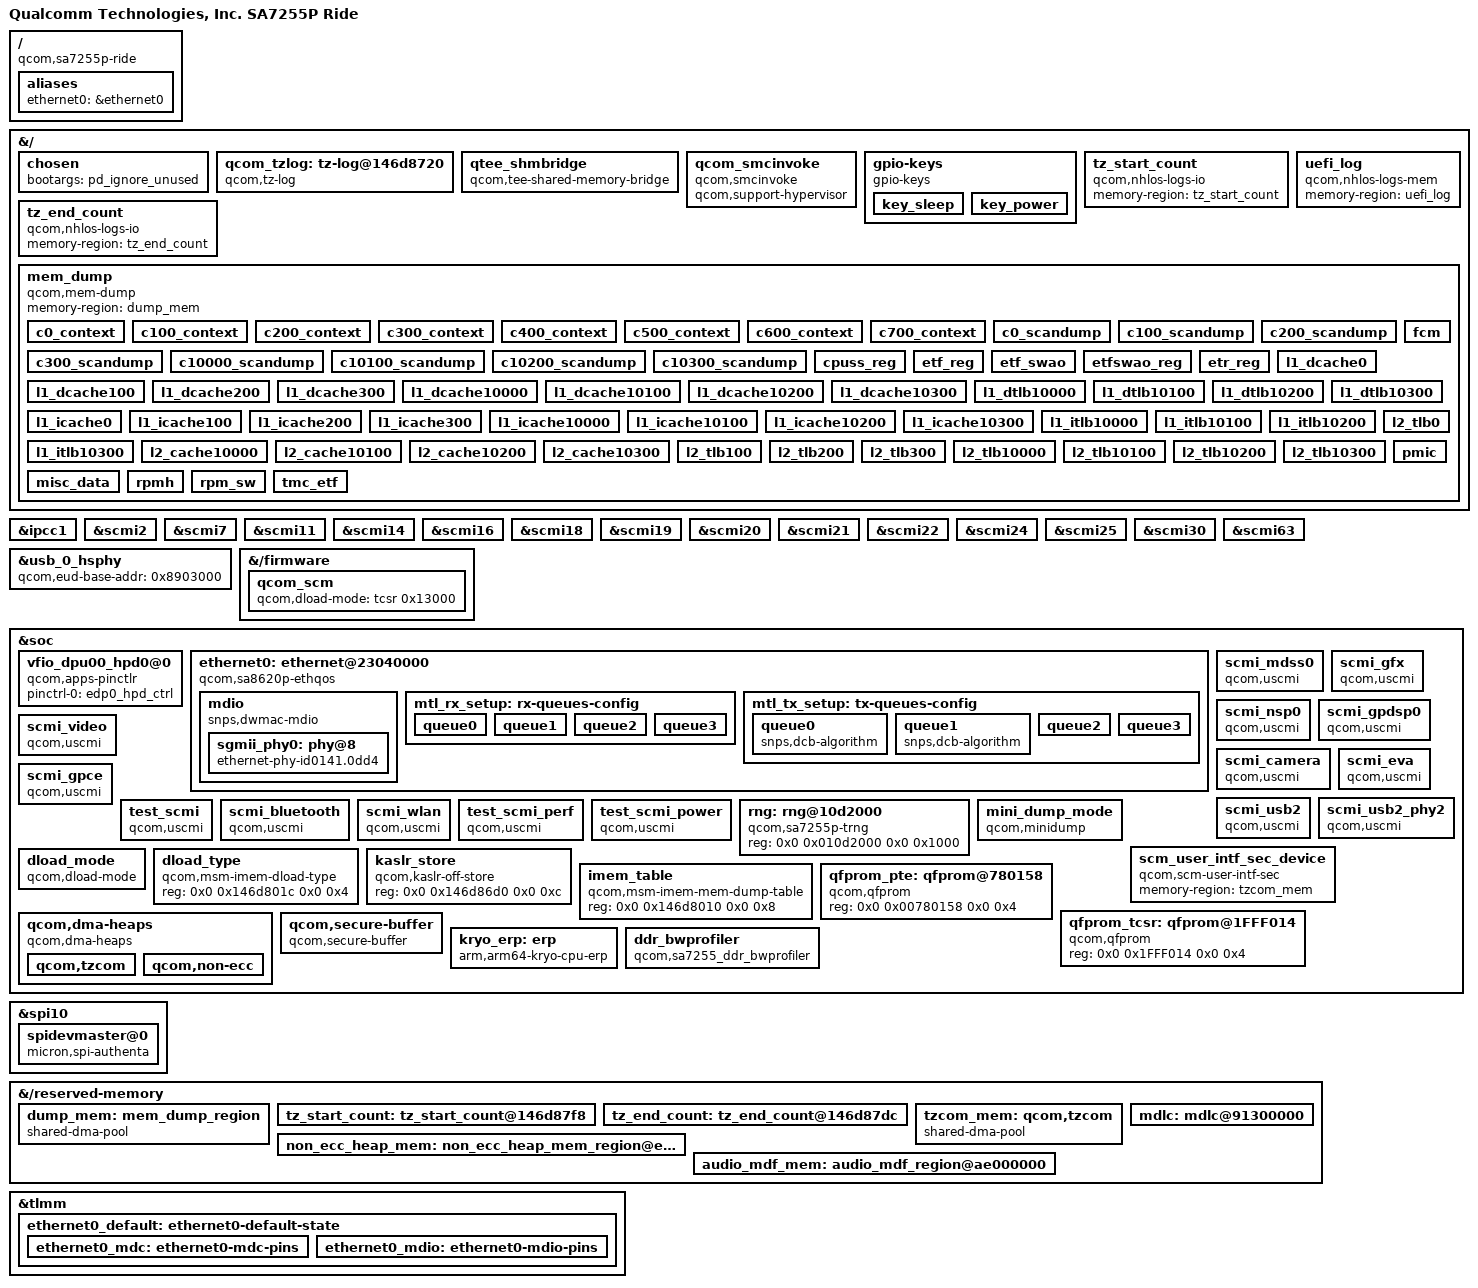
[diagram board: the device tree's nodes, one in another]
// SPDX-License-Identifier: BSD-3-Clause
/*
 * Copyright (c) Qualcomm Technologies, Inc. and/or its subsidiaries.
 */

/dts-v1/;
/plugin/;

#include <dt-bindings/interrupt-controller/irq.h>
#include <dt-bindings/interrupt-controller/arm-gic.h>
#include <dt-bindings/arm/qcom_dma_heap_dt_constants.h>
#include <dt-bindings/input/input.h>
#include <dt-bindings/gpio/gpio.h>
#include <oot-dt-bindings/qcom-ipcc.h>
#include "sa7255p-pinctrl.dtsi"
#include "sa7255p-vfio.dtsi"
#include "sa7255p-cnss.dtsi"

/ {
	model = "Qualcomm Technologies, Inc. SA7255P Ride";
	compatible = "qcom,sa7255p-ride","qcom,sa7255p";

	aliases {
		ethernet0 = &ethernet0;
	};
};

&{/} {

	chosen {
		bootargs = "pd_ignore_unused";
	};

	qcom_tzlog: tz-log@146d8720 {
		compatible = "qcom,tz-log";
		reg = <0 0x146d8720 0 0x3000>;
		qcom,hyplog-enabled;
		qcom,support-hypervisor;
		hyplog-address-offset = <0x410>;
		hyplog-size-offset = <0x414>;
	};

	qtee_shmbridge {
		compatible = "qcom,tee-shared-memory-bridge";
		qcom,support-hypervisor;
		memory-region = <&cma>;
	};

	qcom_smcinvoke {
		compatible = "qcom,smcinvoke";
		qcom,support-hypervisor;
	};

	gpio-keys {
		compatible = "gpio-keys";

		key_sleep {
			label = "sleep";
			linux,code = <KEY_SLEEP>;
			gpios = <&tlmm 3 GPIO_ACTIVE_HIGH>;
			linux,input-type = <1>;
			debounce-interval = <0>;
			wakeup-source;
			wakeup-event-action = <1>;
		};

		key_power {
			label = "power";
			linux,code = <KEY_POWER>;
			gpios = <&tlmm 56 GPIO_ACTIVE_HIGH>;
			linux,input-type = <1>;
			debounce-interval = <0>;
			wakeup-source;
			wakeup-event-action = <1>;
		};
	};

	tz_start_count {
		compatible = "qcom,nhlos-logs-io", "qcom,nhlos-logs";
		memory-region = <&tz_start_count>;
	};

	tz_end_count {
		compatible = "qcom,nhlos-logs-io", "qcom,nhlos-logs";
		memory-region = <&tz_end_count>;
	};

	uefi_log {
		compatible = "qcom,nhlos-logs-mem", "qcom,nhlos-logs";
		memory-region = <&uefi_log>;
	};

	mem_dump {
		compatible = "qcom,mem-dump";
		memory-region = <&dump_mem>;

		c0_context {
			qcom,dump-size = <0x800>;
			qcom,dump-id = <0x0>;
		};

		c100_context {
			qcom,dump-size = <0x800>;
			qcom,dump-id = <0x1>;
		};

		c200_context {
			qcom,dump-size = <0x800>;
			qcom,dump-id = <0x2>;
		};

		c300_context {
			qcom,dump-size = <0x800>;
			qcom,dump-id = <0x3>;
		};

		c400_context {
			qcom,dump-size = <0x800>;
			qcom,dump-id = <0x4>;
		};

		c500_context {
			qcom,dump-size = <0x800>;
			qcom,dump-id = <0x5>;
		};

		c600_context {
			qcom,dump-size = <0x800>;
			qcom,dump-id = <0x6>;
		};

		c700_context {
			qcom,dump-size = <0x800>;
			qcom,dump-id = <0x7>;
		};

		c0_scandump: c0_scandump {
			qcom,dump-size = <0x40000>;
			qcom,dump-id = <0x130>;
		};

		c100_scandump: c100_scandump {
			qcom,dump-size = <0x40000>;
			qcom,dump-id = <0x131>;
		};

		c200_scandump: c200_scandump {
			qcom,dump-size = <0x40000>;
			qcom,dump-id = <0x132>;
		};

		c300_scandump: c300_scandump {
			qcom,dump-size = <0x40000>;
			qcom,dump-id = <0x133>;
		};

		c10000_scandump: c10000_scandump {
			qcom,dump-size = <0x40000>;
			qcom,dump-id = <0x134>;
		};

		c10100_scandump: c10100_scandump {
			qcom,dump-size = <0x40000>;
			qcom,dump-id = <0x135>;
		};

		c10200_scandump: c10200_scandump {
			qcom,dump-size = <0x40000>;
			qcom,dump-id = <0x136>;
		};

		c10300_scandump: c10300_scandump {
			qcom,dump-size = <0x40000>;
			qcom,dump-id = <0x137>;
		};

		cpuss_reg: cpuss_reg {
			qcom,dump-size = <0x20000>;
			qcom,dump-id = <0xef>;
		};

		etf_reg {
			qcom,dump-size = <0x1000>;
			qcom,dump-id = <0x101>;
		};

		etf_swao {
			qcom,dump-size = <0x8400>;
			qcom,dump-id = <0xf1>;
		};

		etfswao_reg {
			qcom,dump-size = <0x1000>;
			qcom,dump-id = <0x102>;
		};

		etr_reg {
			qcom,dump-size = <0x1000>;
			qcom,dump-id = <0x100>;
		};

		fcm {
			qcom,dump-size = <0x8400>;
			qcom,dump-id = <0xee>;
		};

		l1_dcache0 {
			qcom,dump-size = <0x12100>;
			qcom,dump-id = <0x80>;
		};

		l1_dcache100 {
			qcom,dump-size = <0x12100>;
			qcom,dump-id = <0x81>;
		};

		l1_dcache200 {
			qcom,dump-size = <0x12100>;
			qcom,dump-id = <0x82>;
		};

		l1_dcache300 {
			qcom,dump-size = <0x12100>;
			qcom,dump-id = <0x83>;
		};

		l1_dcache10000 {
			qcom,dump-size = <0x12100>;
			qcom,dump-id = <0x84>;
		};

		l1_dcache10100 {
			qcom,dump-size = <0x12100>;
			qcom,dump-id = <0x85>;
		};

		l1_dcache10200 {
			qcom,dump-size = <0x12100>;
			qcom,dump-id = <0x86>;
		};

		l1_dcache10300 {
			qcom,dump-size = <0x12100>;
			qcom,dump-id = <0x87>;
		};

		l1_dtlb10000 {
			qcom,dump-size = <0x300>;
			qcom,dump-id = <0x44>;
		};

		l1_dtlb10100 {
			qcom,dump-size = <0x300>;
			qcom,dump-id = <0x45>;
		};

		l1_dtlb10200 {
			qcom,dump-size = <0x300>;
			qcom,dump-id = <0x46>;
		};

		l1_dtlb10300 {
			qcom,dump-size = <0x300>;
			qcom,dump-id = <0x47>;
		};

		l1_icache0 {
			qcom,dump-size = <0x26100>;
			qcom,dump-id = <0x60>;
		};

		l1_icache100 {
			qcom,dump-size = <0x26100>;
			qcom,dump-id = <0x61>;
		};

		l1_icache200 {
			qcom,dump-size = <0x26100>;
			qcom,dump-id = <0x62>;
		};

		l1_icache300 {
			qcom,dump-size = <0x26100>;
			qcom,dump-id = <0x63>;
		};

		l1_icache10000 {
			qcom,dump-size = <0x26100>;
			qcom,dump-id = <0x64>;
		};

		l1_icache10100 {
			qcom,dump-size = <0x26100>;
			qcom,dump-id = <0x65>;
		};

		l1_icache10200 {
			qcom,dump-size = <0x26100>;
			qcom,dump-id = <0x66>;
		};

		l1_icache10300 {
			qcom,dump-size = <0x26100>;
			qcom,dump-id = <0x67>;
		};

		l1_itlb10000 {
			qcom,dump-size = <0x300>;
			qcom,dump-id = <0x24>;
		};

		l1_itlb10100 {
			qcom,dump-size = <0x300>;
			qcom,dump-id = <0x25>;
		};

		l1_itlb10200 {
			qcom,dump-size = <0x300>;
			qcom,dump-id = <0x26>;
		};

		l1_itlb10300 {
			qcom,dump-size = <0x300>;
			qcom,dump-id = <0x27>;
		};

		l2_cache10000 {
			qcom,dump-size = <0x90100>;
			qcom,dump-id = <0xc4>;
		};

		l2_cache10100 {
			qcom,dump-size = <0x90100>;
			qcom,dump-id = <0xc5>;
		};

		l2_cache10200 {
			qcom,dump-size = <0x90100>;
			qcom,dump-id = <0xc6>;
		};

		l2_cache10300 {
			qcom,dump-size = <0x90100>;
			qcom,dump-id = <0xc7>;
		};

		l2_tlb0 {
			qcom,dump-size = <0x6100>;
			qcom,dump-id = <0x120>;
		};

		l2_tlb100 {
			qcom,dump-size = <0x6100>;
			qcom,dump-id = <0x121>;
		};

		l2_tlb200 {
			qcom,dump-size = <0x6100>;
			qcom,dump-id = <0x122>;
		};

		l2_tlb300 {
			qcom,dump-size = <0x6100>;
			qcom,dump-id = <0x123>;
		};

		l2_tlb10000 {
			qcom,dump-size = <0x6100>;
			qcom,dump-id = <0x124>;
		};

		l2_tlb10100 {
			qcom,dump-size = <0x6100>;
			qcom,dump-id = <0x125>;
		};

		l2_tlb10200 {
			qcom,dump-size = <0x6100>;
			qcom,dump-id = <0x126>;
		};

		l2_tlb10300 {
			qcom,dump-size = <0x6100>;
			qcom,dump-id = <0x127>;
		};

		misc_data {
			qcom,dump-size = <0x1000>;
			qcom,dump-id = <0xe8>;
		};

		pmic {
			qcom,dump-size = <0x80000>;
			qcom,dump-id = <0xe4>;
		};

		rpmh {
			qcom,dump-size = <0x2000000>;
			qcom,dump-id = <0xec>;
		};

		rpm_sw {
			qcom,dump-size = <0x28000>;
			qcom,dump-id = <0xea>;
		};

		tmc_etf {
			qcom,dump-size = <0x10000>;
			qcom,dump-id = <0xf0>;
		};
	};
};

&ipcc1 {
	status = "okay";
};

&scmi2 {
	status = "okay";
};

&scmi7 {
	status = "okay";
};

&scmi11 {
	status = "okay";
};

&scmi14 {
	status = "okay";
};

&scmi16 {
	status = "okay";
};

&scmi18 {
	status = "okay";
};

&scmi19 {
	status = "okay";
};

&scmi20 {
	status = "okay";
};

&scmi21 {
	status = "okay";
};

&scmi22 {
	status = "okay";
};

&scmi24 {
	status = "okay";
};

&scmi25 {
	status = "okay";
};

&scmi30 {
	status = "okay";
};

&scmi63 {
	status = "okay";
};

&usb_0_hsphy {
	qcom,eud-base-addr = <0x8903000>;
};

&{/firmware} {
        qcom_scm {
                qcom,dload-mode = <&tcsr 0x13000>;
        };
};

&soc {
	vfio_dpu00_hpd0@0 {
		compatible = "qcom,apps-pinctlr";
		pinctrl-names = "default";
		pinctrl-0 = <&edp0_hpd_ctrl>;
	};

	ethernet0: ethernet@23040000 {
			compatible = "qcom,sa8620p-ethqos";
			reg = <0x0 0x23040000 0x0 0x10000>,
				<0x0 0x23056000 0x0 0x100>;
			reg-names = "stmmaceth", "rgmii";

			interrupts = <GIC_SPI 946 IRQ_TYPE_LEVEL_HIGH>,
				<GIC_SPI 782 IRQ_TYPE_LEVEL_HIGH>;
			interrupt-names = "macirq", "sfty";

			iommus = <&apps_smmu 0x120 0xf>;
			dma-coherent;

			snps,tso;
			snps,pbl = <32>;
			rx-fifo-depth = <16384>;
			tx-fifo-depth = <20480>;

	};
	scmi_mdss0 {
		compatible = "qcom,uscmi";
		power-domains = <&scmi16_dvfs 0>;
		power-domain-names = "perf";
		qcom,dev-name = "scmi_mdss0";
	};

	scmi_gfx {
		compatible = "qcom,uscmi";
		power-domains = <&scmi18_dvfs 0>;
		power-domain-names = "perf";
		qcom,dev-name = "scmi_gfx";
	};

	scmi_nsp0 {
		compatible = "qcom,uscmi";

		power-domains = <&scmi19_dvfs 0>;
		power-domain-names = "perf";

		qcom,dev-name = "scmi_nsp0";
	};

	scmi_gpdsp0 {
		compatible = "qcom,uscmi";

		power-domains = <&scmi19_dvfs 1>;
		power-domain-names = "perf";

		qcom,dev-name = "scmi_gpdsp0";
	};

	scmi_video {
		compatible = "qcom,uscmi";

		power-domains = <&scmi20_dvfs 0>, <&scmi20_dvfs 1>;
		power-domain-names = "perf_video_clk", "perf_video_bw";

		resets = <&scmi20_rst 0>;
		reset-names = "reset_video";

		qcom,dev-name = "scmi_video";
	};

	scmi_camera {
		compatible = "qcom,uscmi";
		power-domains = <&scmi21_dvfs 0>;
		power-domain-names = "perf_camera";
		qcom,dev-name = "scmi_camera";
	};

	scmi_eva {
		compatible = "qcom,uscmi";

		power-domains = <&scmi22_dvfs 0>, <&scmi22_dvfs 1>;
		power-domain-names = "perf_eva_clk", "perf_eva_bw";

		qcom,dev-name = "scmi_eva";
	};

	scmi_gpce {
		compatible = "qcom,uscmi";

		power-domains = <&scmi30_dvfs 0>;
		power-domain-names = "gpce_clock";

		qcom,dev-name = "scmi_gpce";
	};

	/* SCMI node for USB2 controller power management */
	scmi_usb2 {
		compatible = "qcom,uscmi";

		power-domains = <&scmi2_pd 0>, <&scmi2_pd 1>;
		power-domain-names = "usb_transfer", "usb_core";

		qcom,dev-name = "scmi_usb2";
	};

	scmi_usb2_phy2 {
		compatible = "qcom,uscmi";

		power-domains = <&scmi14_pd 0>, <&scmi14_pd 1>;
		power-domain-names = "usb_transfer", "usb_core";

		qcom,dev-name = "scmi_usb2_phy2";
	};

	test_scmi {
		compatible = "qcom,uscmi";

		power-domains = <&scmi63_pd 2> , <&scmi63_dvfs 2>;
		power-domain-names = "power", "perf";

		resets = <&scmi63_rst 0>;
		reset-names = "core";

		qcom,dev-name = "test_scmi";
	};

	scmi_bluetooth {
		compatible = "qcom,uscmi";
		power-domains = <&scmi25_pd 0>, <&scmi25_pd 1>;
		power-domain-names = "power_regulator", "power_gpio";
		qcom,dev-name = "scmi_bluetooth";
	};

	scmi_wlan {
		compatible = "qcom,uscmi";
		power-domains = <&scmi24_pd 0>, <&scmi24_pd 1>;
		power-domain-names = "power_regulator", "power_gpio";
		qcom,dev-name = "scmi_wlan";
	};

	test_scmi_perf {
		compatible = "qcom,uscmi";

		power-domains = <&scmi63_dvfs 1>;
		power-domain-names = "perf";

		qcom,dev-name = "test_scmi_perf";
	};

	test_scmi_power {
		compatible = "qcom,uscmi";

		power-domains = <&scmi63_pd 1>;

		qcom,dev-name = "test_scmi_power";
	};

	rng: rng@10d2000 {
		compatible = "qcom,sa7255p-trng", "qcom,trng";
		reg = <0x0 0x010d2000 0x0 0x1000>;
	};

	mini_dump_mode {
		compatible = "qcom,minidump";
	};

	scm_user_intf_sec_device {
		compatible = "qcom,scm-user-intf-sec";
		memory-region = <&tzcom_mem>;
		status = "ok";
	};

	dload_mode {
		compatible = "qcom,dload-mode";
	};

	dload_type {
		compatible = "qcom,msm-imem-dload-type";
		reg = <0x0 0x146d801c 0x0 0x4>;
	};

	kaslr_store {
		compatible = "qcom,kaslr-off-store";
		reg = <0x0 0x146d86d0 0x0 0xc>;
	};

	imem_table {
		compatible = "qcom,msm-imem-mem-dump-table";
		reg = <0x0 0x146d8010 0x0 0x8>;
	};

	qfprom_pte: qfprom@780158 {
		compatible = "qcom,qfprom";
		reg = <0x0 0x00780158 0x0 0x4>;
		#address-cells = <2>;
		#size-cells = <2>;
	};

	qfprom_tcsr: qfprom@1FFF014 {
		compatible = "qcom,qfprom";
		reg = <0x0 0x1FFF014 0x0 0x4>;
		#address-cells = <2>;
		#size-cells = <2>;
	};

	qcom,dma-heaps {
		compatible = "qcom,dma-heaps";
		status = "okay";

		qcom,tzcom {
			qcom,dma-heap-name = "qcom,tzcom";
			qcom,dma-heap-type = <HEAP_TYPE_CMA>;
			memory-region = <&tzcom_mem>;
		};

		qcom,non-ecc {
			qcom,dma-heap-name = "qcom,non-ecc";
			qcom,dma-heap-type = <HEAP_TYPE_CARVEOUT>;
			memory-region = <&non_ecc_heap_mem>;
		};
	};

	qcom,secure-buffer {
		compatible = "qcom,secure-buffer";
	};

	kryo_erp: erp {
		compatible = "arm,arm64-kryo-cpu-erp";
		interrupts = <GIC_PPI 0 IRQ_TYPE_LEVEL_LOW>,
				<GIC_SPI 36 IRQ_TYPE_LEVEL_HIGH>,
				<GIC_SPI 21 IRQ_TYPE_LEVEL_HIGH>;
		interrupt-names = "l1-l2-faultirq",
					"l3-c0-scu-faultirq",
					"l3-c1-scu-faultirq";
	};

	ddr_bwprofiler {
		compatible = "qcom,sa7255_ddr_bwprofiler";
		reg = <0x0 0x9200000 0x0 0x100000>,
			<0x0 0x9300000 0x0 0x100000>,
			<0x0 0x9400000 0x0 0x100000>,
			<0x0 0x9500000 0x0 0x100000>,
			<0x0 0x915b000 0x0 0x001000>,
			<0x0 0x915c000 0x0 0x001000>,
			<0x0 0x915d000 0x0 0x001000>,
			<0x0 0x915e000 0x0 0x001000>,
			<0x0 0x17A0000 0x0 0x040000>;
	};
};

&spi10 {
	spidevmaster@0 {
		/* FIXME: Replace below compatible once we have proper dt-bindings
		 * for the NXPs Mercury Audio DSP SAF4000EL/101(ES).
		 */
		compatible = "micron,spi-authenta";
		reg = <0>;
		spi-max-frequency = <10000000>;
		spi-cpha;
		status = "okay";
	};
};

&{/reserved-memory} {
	#address-cells = <2>;
	#size-cells = <2>;
	ranges;

	dump_mem: mem_dump_region {
		alloc-ranges = <0x0 0x00000000 0x0 0xffffffff>;
		compatible = "shared-dma-pool";
		reusable;
		size = <0x0 0x3000000>;
	};

	tz_start_count: tz_start_count@146d87f8 {
		reg = <0x0 0x146d87f8 0x0 0x8>;
		no-map;
	};

	tz_end_count: tz_end_count@146d87dc {
		reg = <0x0 0x146d87dc 0x0 0x8>;
		no-map;
	};

	tzcom_mem: qcom,tzcom {
		compatible = "shared-dma-pool";
		alloc-ranges = <0x0 0x00000000 0x0 0xffffffff>;
		reusable;
		alignment = <0x0 0x400000>;
		size = <0x0 0x1400000>; /* 20M */
	};

	non_ecc_heap_mem: non_ecc_heap_mem_region@edb9a0000 {
		reg = <0xe 0xdb9a0000 0x0 0x20000000>;
		no-map;
	};

	audio_mdf_mem: audio_mdf_region@ae000000 {
		reg = <0x0 0xae000000 0x0 0x1000000>;
		no-map;
	};

	mdlc: mdlc@91300000 {
		no-map;
		reg = <0x0 0x91300000 0x0 0x10000>;
	};

};

&ethernet0 {
	phy-mode = "sgmii";
	iommus = <&apps_smmu 0x120 0x7>;
	phy-handle = <&sgmii_phy0>;

	pinctrl-0 = <&ethernet0_default>;
	pinctrl-names = "default";

	snps,mtl-rx-config = <&mtl_rx_setup>;
	snps,mtl-tx-config = <&mtl_tx_setup>;
	snps,ps-speed = <1000>;

	power-domains = <&scmi7_pd 0>, <&scmi7_pd 1>,<&scmi7_dvfs 0>;
	power-domain-names = "power_core", "power_mdio","perf_serdes";

	status = "okay";

	mdio {
		compatible = "snps,dwmac-mdio";
		#address-cells = <1>;
		#size-cells = <0>;

		sgmii_phy0: phy@8 {
			compatible = "ethernet-phy-id0141.0dd4";
			reg = <0x8>;
			device_type = "ethernet-phy";
			interrupts-extended = <&tlmm 4 IRQ_TYPE_EDGE_FALLING>;
			reset-gpios = <&tlmm 31 GPIO_ACTIVE_LOW>;
			reset-assert-us = <11000>;
			reset-deassert-us = <70000>;
		};
	};

	mtl_rx_setup: rx-queues-config {
		snps,rx-queues-to-use = <4>;
		snps,rx-sched-sp;

		queue0 {
			snps,dcb-algorithm;
			snps,map-to-dma-channel = <0x0>;
			snps,route-up;
			snps,priority = <0x1>;
		};

		queue1 {
			snps,dcb-algorithm;
			snps,map-to-dma-channel = <0x1>;
			snps,route-ptp;
		};

		queue2 {
			snps,avb-algorithm;
			snps,map-to-dma-channel = <0x2>;
			snps,route-avcp;
		};

		queue3 {
			snps,avb-algorithm;
			snps,map-to-dma-channel = <0x3>;
			snps,priority = <0xc>;
		};
	};

	mtl_tx_setup: tx-queues-config {
		snps,tx-queues-to-use = <4>;
		snps,tx-sched-sp;

		queue0 {
			snps,dcb-algorithm;
		};

		queue1 {
			snps,dcb-algorithm;
		};

		queue2 {
			snps,avb-algorithm;
			snps,send_slope = <0x1000>;
			snps,idle_slope = <0x1000>;
			snps,high_credit = <0x3e800>;
			snps,low_credit = <0xffc18000>;
		};

		queue3 {
			snps,avb-algorithm;
			snps,send_slope = <0x1000>;
			snps,idle_slope = <0x1000>;
			snps,high_credit = <0x3e800>;
			snps,low_credit = <0xffc18000>;
		};
	};
};

&tlmm {
	ethernet0_default: ethernet0-default-state {
		ethernet0_mdc: ethernet0-mdc-pins {
			pins = "gpio5";
			function = "emac0_mdc";
			drive-strength = <16>;
			bias-pull-up;
		};

		ethernet0_mdio: ethernet0-mdio-pins {
			pins = "gpio6";
			function = "emac0_mdio";
			drive-strength = <16>;
			bias-pull-up;
		};
	};
};
